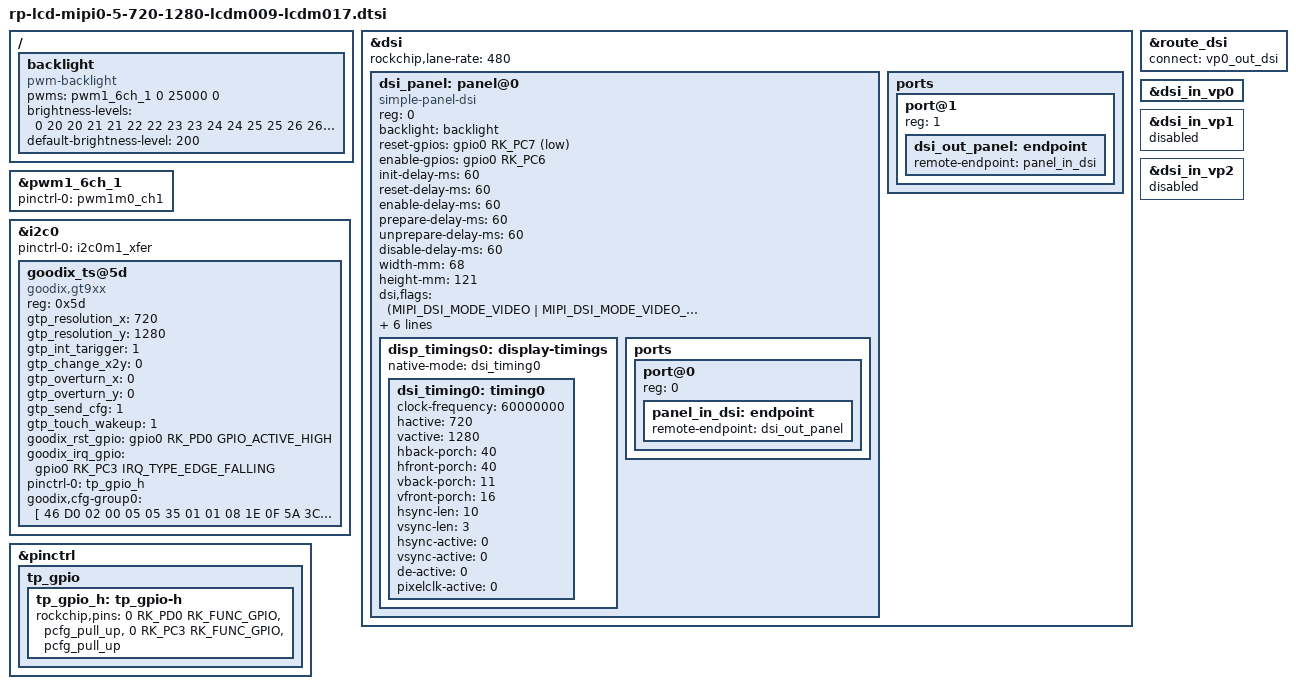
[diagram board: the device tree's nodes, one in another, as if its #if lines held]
/{
    backlight: backlight {
        compatible = "pwm-backlight";
        pwms = <&pwm1_6ch_1 0 25000 0>;
        brightness-levels = <
              0  20  20  21  21  22  22  23
             23  24  24  25  25  26  26  27
             27  28  28  29  29  30  30  31
             31  32  32  33  33  34  34  35
             35  36  36  37  37  38  38  39
             40  41  42  43  44  45  46  47
             48  49  50  51  52  53  54  55
             56  57  58  59  60  61  62  63
             64  65  66  67  68  69  70  71
             72  73  74  75  76  77  78  79
             80  81  82  83  84  85  86  87
             88  89  90  91  92  93  94  95
             96  97  98  99 100 101 102 103
            104 105 106 107 108 109 110 111
            112 113 114 115 116 117 118 119
            120 121 122 123 124 125 126 127
            128 129 130 131 132 133 134 135
            136 137 138 139 140 141 142 143
            144 145 146 147 148 149 150 151
            152 153 154 155 156 157 158 159
            160 161 162 163 164 165 166 167
            168 169 170 171 172 173 174 175
            176 177 178 179 180 181 182 183
            184 185 186 187 188 189 190 191
            192 193 194 195 196 197 198 199
            200 201 202 203 204 205 206 207
            208 209 210 211 212 213 214 215
            216 217 218 219 220 221 222 223
            224 225 226 227 228 229 230 231
            232 233 234 235 236 237 238 239
            240 241 242 243 244 245 246 247
            248 249 250 251 252 253 254 255
        >;
        default-brightness-level = <200>;
    };
};



&dsi {
    status = "okay";
    rockchip,lane-rate = <480>;
    dsi_panel: panel@0 {
        status = "okay";
        compatible = "simple-panel-dsi";
        reg = <0>;
        backlight = <&backlight>;
        
        reset-gpios = <&gpio0 RK_PC7 GPIO_ACTIVE_LOW>;
        enable-gpios = <&gpio0 RK_PC6 GPIO_ACTIVE_HIGH>;
 init-delay-ms = <60>;
        reset-delay-ms = <60>;
        enable-delay-ms = <60>;
        prepare-delay-ms = <60>;
        unprepare-delay-ms = <60>;
        disable-delay-ms = <60>;        
        
	width-mm = <68>;
        height-mm = <121>;
        dsi,flags = <(MIPI_DSI_MODE_VIDEO | MIPI_DSI_MODE_VIDEO_BURST |
                  MIPI_DSI_MODE_LPM | MIPI_DSI_MODE_NO_EOT_PACKET)>;
        dsi,format = <MIPI_DSI_FMT_RGB888>;
        dsi,lanes  = <4>;
        panel-init-sequence = [
            39 00 04 B9 F1 12 83

            39 00 0B B3 07 0B 1E 1E 03 FF 00 00 00 00

            39 00 02 BC 46

            39 00 02 CC 0B

            39 00 02 B4 80

            39 00 04 B2 C8 12 A0

            39 00 0F E3 07 07 0B 0B 03 0B 00 00 00 00 FF 80 C0 10

            39 00 0D C1 53 00 32 32 77 F1 FF FF CC CC 77 77

            39 00 03 B5 09 09

            39 00 03 B6 B7 B7

            39 00 40 E9 C2 10 0A 00 00 81 80 12 30 00 37 86 81 80 37 18 00 05 00 00 00 00 00 05 00 00 00 00 F8 BA 46 02 08 28 88 88 88 88 88 F8 BA 57 13 18 38 88 88 88 88 88 00 00 00 03 00 00 00 00 00 00 00 00 00

            39 00 3E EA 07 12 01 01 02 3C 00 00 00 00 00 00 8F BA 31 75 38 18 88 88 88 88 88 8F BA 20 64 28 08 88 88 88 88 88 23 10 00 00 04 00 00 00 00 00 00 00 00 00 00 00 00 00 00 00 00 00 00 00 00 00 00

            39 00 23 E0 00 02 04 1A 23 3F 2C 28 05 09 0B 10 11 10 12 12 19 00 02 04 1A 23 3F 2C 28 05 09 0B 10 11 10 12 12 19



            05 78 01 11
            05 00 01 29
        ];

        panel-exit-sequence = [
            05 00 01 28
            05 00 01 10
        ];

        disp_timings0: display-timings {
            native-mode = <&dsi_timing0>;
            dsi_timing0: timing0 {
		clock-frequency = <60000000>;
                                hactive = <720>;
                                vactive = <1280>;
                                hback-porch = <40>;
                                hfront-porch = <40>;
                                vback-porch = <11>;
                                vfront-porch = <16>;
                                hsync-len = <10>;
                                vsync-len = <3>;
                hsync-active = <0>;
                vsync-active = <0>;
                de-active = <0>;
                pixelclk-active = <0>;

            };
        };

        ports {
            #address-cells = <1>;
            #size-cells = <0>;

            port@0 {
                reg = <0>;
                panel_in_dsi: endpoint {
                    remote-endpoint = <&dsi_out_panel>;
                };
            };
        };
    };

    ports {
        #address-cells = <1>;
        #size-cells = <0>;

        port@1 {
            reg = <1>;
            dsi_out_panel: endpoint {
                remote-endpoint = <&panel_in_dsi>;
            };
        };
    };

};

#if defined RP_RK3576S || defined DR4_RK3576X || defined PRO_RK3576X

&route_dsi {
    status = "okay";
    connect = <&vp0_out_dsi>;
};

&pwm1_6ch_1 {
    status = "okay";
    pinctrl-0 = <&pwm1m0_ch1>;
};

&dsi_in_vp0 {
    status = "okay";
};

&dsi_in_vp1 {
    status = "disabled";
};

&dsi_in_vp2 {
    status = "disabled";
};


#else  //rk3576

&route_dsi {
    status = "okay";
};

&pwm1_6ch_1 {
    status = "okay";
    pinctrl-0 = <&pwm1m0_ch1>;
};

//default to hdmi
&dsi_in_vp0 {
    status = "disabled";
};

&dsi_in_vp1 {
    status = "okay";
};

&dsi_in_vp2 {
    status = "disabled";
};

&dsi_in_vopl {
    status = "okay";
};
#endif


//TP
&i2c0 {
    status = "okay";
    pinctrl-names = "default";
    pinctrl-0 = <&i2c0m1_xfer>;
    goodix_ts@5d {
        compatible = "goodix,gt9xx";
        reg = <0x5d>;
        gtp_resolution_x = <720>;
        gtp_resolution_y = <1280>;
        gtp_int_tarigger = <1>;
        gtp_change_x2y = <0>;
        gtp_overturn_x = <0>;
        gtp_overturn_y = <0>;
        gtp_send_cfg = <1>;
        gtp_touch_wakeup = <1>;
        goodix_rst_gpio = <&gpio0 RK_PD0 GPIO_ACTIVE_HIGH>;
        goodix_irq_gpio = <&gpio0 RK_PC3 IRQ_TYPE_EDGE_FALLING>;
				pinctrl-names = "default";
      	pinctrl-0 = <&tp_gpio_h>;
        goodix,cfg-group0 = [    //old touch
   		        46 D0 02 00 05 05 35 01 01 08 1E 0F 5A 3C
                        03 05 00 00 00 00 11 11 00 19 1B 1E 14 89
                        29 0A 41 43 D3 07 00 00 00 9A 02 11 00 01
                        05 00 00 00 00 09 11 00 00 36 4A 94 45 00
                        00 00 00 00 94 37 00 8B 3B 00 83 3F 00 7C
                        43 00 76 47 00 76 10 30 48 00 F0 4A 3A FF
                        FF 27 00 00 00 00 00 00 00 00 00 00 00 00
                        00 00 00 00 00 00 00 00 00 00 00 00 00 00
                        08 0A 0C 0E 10 12 14 16 18 1A 00 00 00 00
                        00 00 00 00 00 00 00 00 00 00 00 00 00 00
                        00 00 0E 0C 0A 08 06 05 04 02 00 1D 1E 1F
                        20 22 24 28 29 2A 00 00 00 00 00 00 00 00
                        00 00 00 00 00 00 00 00 00 00 00 00 00 00
                        00 00 84 01
	 ];
	};
};

&pinctrl {
    tp_gpio {
		tp_gpio_h: tp_gpio-h {
			rockchip,pins = <0 RK_PD0 RK_FUNC_GPIO &pcfg_pull_up>,
                            <0 RK_PC3 RK_FUNC_GPIO &pcfg_pull_up>;
		};
	};
};

